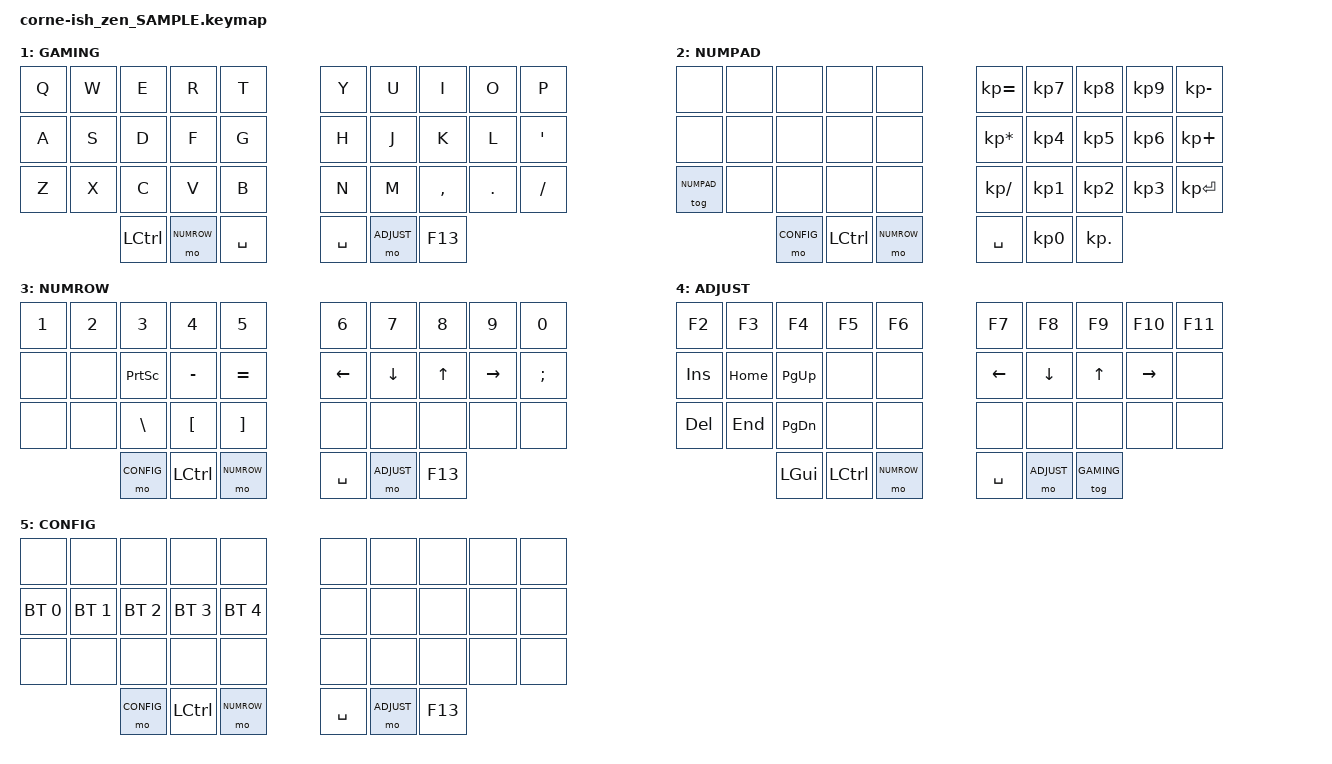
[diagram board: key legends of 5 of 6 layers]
/*
*
* Copyright (c) 2021 lowprokb.ca
* SPDX-License-Identifier: MIT
*
*/

#include <behaviors.dtsi>
#include <dt-bindings/zmk/keys.h>
#include <dt-bindings/zmk/bt.h>

#define QWERTY 0
#define GAMING 1
#define NUMPAD 2
#define NUMROW 3
#define ADJUST 4
#define CONFIG 5

/ {
        keymap {
                compatible = "zmk,keymap";

                default_layer {
                        label = "QWERTY";
                        bindings = <
   &kp Q &kp W &kp E &kp R &kp T    &kp Y &kp U &kp I    &kp O   &kp P
   &kp A &kp S &kp D &kp F &kp G    &kp H &kp J &kp K    &kp L   &kp QUOT
   &kp Z &kp X &kp C &kp V &kp B    &kp N &kp M &kp CMMA &kp DOT &kp FSLH
              &kp LGUI &kp LCTL &mo NUMROW    &kp SPC &mo ADJUST
                        >;
                };

                gaming_layer {
                        label = "GAMING";
                        bindings = <
   &kp Q &kp W &kp E &kp R &kp T    &kp Y &kp U &kp I    &kp O   &kp P
   &kp A &kp S &kp D &kp F &kp G    &kp H &kp J &kp K    &kp L   &kp QUOT
  &kp Z &kp X &kp C &kp V &kp B    &kp N &kp M &kp CMMA &kp DOT &kp FSLH
               &kp LCTL &mo NUMROW &kp SPC    &kp SPC &mo ADJUST &kp F13
                        >;
                };

                numpad_layer {
                        label = "NUMPAD";
                        bindings = < 
   &none &none &none &none &none    &kp KP_EQUAL    &kp KP_N7 &kp KP_N8 &kp KP_N9 &kp KP_MINUS 
   &none &none &none &none &none    &kp KP_ASTERISK &kp KP_N4 &kp KP_N5 &kp KP_N6 &kp KP_PLUS
   &tog NUMPAD &none &none &none &none    &kp KP_SLASH    &kp KP_N1 &kp KP_N2 &kp KP_N3 &kp KP_ENTER
              &mo CONFIG &kp LCTL &mo NUMROW    &kp SPC &kp KP_N0 &kp KP_DOT
                        >;
                };

                numrow_layer {
                        label = "NUMROW";
                        bindings = <
   &kp N1 &kp N2 &kp N3    &kp N4    &kp N5       &kp N6   &kp N7   &kp N8 &kp N9    &kp N0
   &none  &none  &kp PSCRN &kp MINUS &kp EQUAL    &kp LEFT &kp DOWN &kp UP &kp RIGHT &kp SEMI
   &none  &none  &kp BSLH  &kp LBKT  &kp RBKT     &none    &none    &none  &none     &none
                          &mo CONFIG &kp LCTL &mo NUMROW    &kp SPC &mo ADJUST &kp F13
                        >;
                };

                adjust_layer {
                        label = "ADJUST";
                        bindings = <
   &kp F2  &kp F3   &kp F4    &kp F5 &kp F6    &kp F7   &kp F8   &kp F9 &kp F10   &kp F11
   &kp INS &kp HOME &kp PG_UP &none  &none     &kp LEFT &kp DOWN &kp UP &kp RIGHT &none
   &kp DEL &kp END  &kp PG_DN &none  &none     &none    &none    &none  &none     &none
                           &kp LGUI &kp LCTL &mo NUMROW    &kp SPC &mo ADJUST &tog GAMING
                        >;
                };

                config_layer {
                        label = "CONFIG";
                        bindings = <
   &none        &none        &none        &none        &none           &none &none &none &none &none
   &bt BT_SEL 0 &bt BT_SEL 1 &bt BT_SEL 2 &bt BT_SEL 3 &bt BT_SEL 4    &none &none &none &none &none
   &none        &none        &none        &none        &none           &none &none &none &none &none
                                                &mo CONFIG &kp LCTL &mo NUMROW    &kp SPC &mo ADJUST &kp F13
                        >;
                };
        };
};
